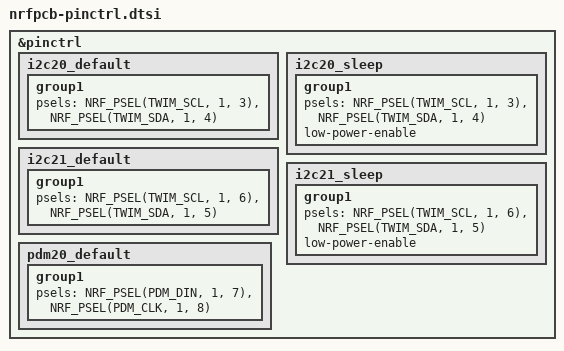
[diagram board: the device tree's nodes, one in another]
/*
 * Pin configuration
 */
&pinctrl {

	/*
	 * I²C pin assignments
	 */
	// Always-on I²C uses pin 1.03 for SCL and 1.04 for SDA.
	i2c20_default: i2c20_default {
		group1 {
			psels = <NRF_PSEL(TWIM_SCL, 1, 3)>,
				<NRF_PSEL(TWIM_SDA, 1, 4)>;
		};
	};
	i2c20_sleep: i2c20_sleep {
		group1 {
			psels = <NRF_PSEL(TWIM_SCL, 1, 3)>,
				<NRF_PSEL(TWIM_SDA, 1, 4)>;
			low-power-enable;
		};
	};

	// Gated I²C uses pin 1.06 for SCL and 1.05 for SDA.
	i2c21_default: i2c21_default {
		group1 {
			psels = <NRF_PSEL(TWIM_SCL, 1, 6)>,
				<NRF_PSEL(TWIM_SDA, 1, 5)>;
		};
	};
	i2c21_sleep: i2c21_sleep {
		group1 {
			psels = <NRF_PSEL(TWIM_SCL, 1, 6)>,
				<NRF_PSEL(TWIM_SDA, 1, 5)>;
			low-power-enable;
		};
	};

	/*
	 * PDM pin assigments
	 */
	// P1.07 for data, P1.08 for clock. SELECT is delegated to a GPIO.
	pdm20_default: pdm20_default {
		group1 {
			psels = <NRF_PSEL(PDM_DIN, 1, 7)>,
				<NRF_PSEL(PDM_CLK, 1, 8)>;
		};
	};
};
